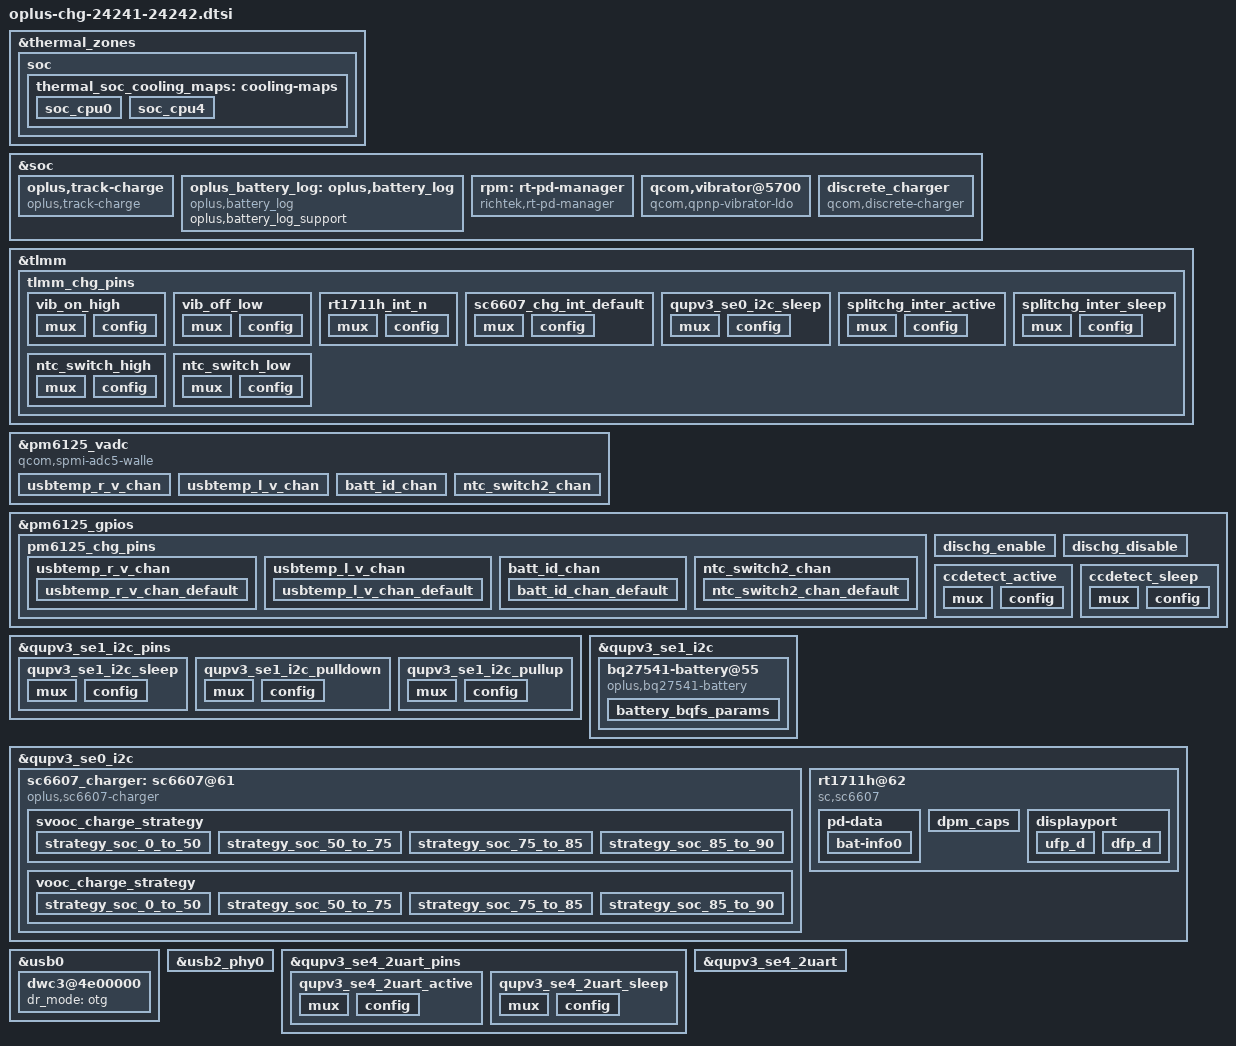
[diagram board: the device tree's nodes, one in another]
#include <dt-bindings/iio/qti_power_supply_iio.h>

&thermal_zones {
	soc {
		thermal_soc_cooling_maps: cooling-maps {
			soc_cpu0 {
				cooling-device =
					<&CPU0 (THERMAL_MAX_LIMIT-4)
						(THERMAL_MAX_LIMIT-4)>;
			};

			soc_cpu4 {
				cooling-device =
					<&CPU4 (THERMAL_MAX_LIMIT-4)
						(THERMAL_MAX_LIMIT-4)>;
			};

			/*soc_cpu6 {
				cooling-device = <&cpu6_isolate 1 1>;
			};

			soc_cpu7 {
				cooling-device = <&cpu7_isolate 1 1>;
			};*/
		};
	};
};

&soc {
	oplus,track-charge {
		compatible = "oplus,track-charge";
		track,fast_chg_break_t_thd = <1000>;
		track,general_chg_break_t_thd = <200>;
		track,voocphy_type = <2>;
		track,wired_max_power = <45000>;
		track,wired_fast_chg_scheme = <4>;
		track,gauge_status_ctrl;
		track,nominal_qmax1 = <5166>;
		track,nominal_fcc1 = <4700>;
		track,external_gauge_num = <1>;
	};

	oplus_battery_log: oplus,battery_log {
		compatible = "oplus,battery_log";
		oplus,battery_log_support;
	};
};

&tlmm {
	tlmm_chg_pins: tlmm_chg_pins {
		vib_on_high: vib_on_high {
			mux {
				pins = "gpio100";
				function = "gpio";
			};

			config {
				pins = "gpio100";
				drive-strength = <2>;
				output-high;
			};
		};
		vib_off_low: vib_off_low {
			mux {
				pins = "gpio100";
				function = "gpio";
			};

			config {
				pins = "gpio100";
				drive-strength = <2>;
				output-low;
			};
		};

		rt1711h_int_n: rt1711h_int_n {
			mux {
				pins = "gpio89";
				function = "gpio";
			};

			config {
				pins = "gpio89";
				drive-strength = <2>;
				bias-disable;
			};
		};

		sc6607_chg_int_default: sc6607_chg_int_default {
			mux {
				pins = "gpio32";
				function = "gpio";
			};

			config {
				pins = "gpio32";
				drive-strength = <2>;
				bias-disable;
			};
		};
		qupv3_se0_i2c_sleep: qupv3_se0_i2c_sleep {
				mux {
					pins = "gpio0", "gpio1";
					function = "gpio";
				};

				config {
					pins = "gpio0", "gpio1";
					drive-strength = <2>;
					bias-no-pull;
					output-high;
				};
		};
		/*split_chg*/
		splitchg_inter_active: splitchg_inter_active {
			mux {
				pins = "gpio32";
				function = "gpio";
			};
			config {
				pins = "gpio32";
				drive-strength = <2>;
				bias-pull-up;
			};
		};

		splitchg_inter_sleep: splitchg_inter_sleep {
			mux {
				pins = "gpio32";
				function = "gpio";
			};
			config {
				pins = "gpio32";
				drive-strength = <2>;
				bias-pull-up;
			};
		};

		ntc_switch_high: ntc_switch_high {
			mux {
				pins = "gpio85";
				function = "gpio";
			};

			config {
				pins = "gpio85";
				drive-strength = <2>;
				output-high;
			};
		};

		ntc_switch_low: ntc_switch_low {
			mux {
				pins = "gpio85";
				function = "gpio";
			};

			config {
				pins = "gpio85";
				drive-strength = <2>;
				output-low;
			};
		};


	};
};

&pm6125_vadc {
	compatible = "qcom,spmi-adc5-walle";
	pinctrl-0 = <&usbtemp_r_v_chan_default &usbtemp_l_v_chan_default &batt_id_chan_default &ntc_switch2_chan_default>;

	usbtemp_r_v_chan {
		reg = <ADC5_GPIO1_100K_PU>;
		label = "usbtemp_r_v_chan";
		qcom,ratiometric;
		qcom,hw-settle-time = <200>;
		qcom,pre-scaling = <1 1>;
		qcom,scale-fn-type = <ADC_SCALE_HW_CALIB_DEFAULT>;
	};

	usbtemp_l_v_chan {
		reg = <ADC5_GPIO2_100K_PU>;
		label = "usbtemp_l_v_chan";
		qcom,ratiometric;
		qcom,hw-settle-time = <200>;
		qcom,pre-scaling = <1 1>;
		qcom,scale-fn-type = <ADC_SCALE_HW_CALIB_DEFAULT>;
	};

	batt_id_chan {
		reg = <ADC5_GPIO3_100K_PU>;
		label = "batt_id_chan";
		qcom,ratiometric;
		qcom,hw-settle-time = <200>;
		qcom,pre-scaling = <1 1>;
		qcom,scale-fn-type = <ADC_SCALE_HW_CALIB_DEFAULT>;
	};

	ntc_switch2_chan {
		reg = <ADC5_GPIO4_100K_PU>;
		label = "ntc_switch2_chan";
		qcom,ratiometric;
		qcom,hw-settle-time = <200>;
		qcom,pre-scaling = <1 1>;
		qcom,scale-fn-type = <ADC_SCALE_HW_CALIB_DEFAULT>;
	};
};

&pm6125_gpios {
	pm6125_chg_pins: pm6125_chg_pins {
			usbtemp_r_v_chan {
				usbtemp_r_v_chan_default: usbtemp_r_v_chan_default {
					pins = "gpio3";
					bias-high-impedance;
				};
			};

			usbtemp_l_v_chan {
				usbtemp_l_v_chan_default: usbtemp_l_v_chan_default {
					pins = "gpio4";
					bias-high-impedance;
				};
			};

			batt_id_chan {
				batt_id_chan_default: batt_id_chan_default {
					pins = "gpio6";
					bias-high-impedance;
				};
			};

			ntc_switch2_chan {
				ntc_switch2_chan_default: ntc_switch2_chan_default {
					pins = "gpio7";
					bias-high-impedance;
				};
			};
	};
	dischg_enable: dischg_enable {
		pins = "gpio8";
		function = "normal";
		power-source = <0>;
		output-high;
		input-disable;
		qcom,drive-strength = <2>;
	};

	dischg_disable: dischg_disable {
		pins = "gpio8";
		function = "normal";
		power-source = <0>;
		output-low;
		input-disable;
		qcom,drive-strength = <2>;
	};

	ccdetect_active: ccdetect_active {
		mux {
			pins = "gpio102";
			function = "gpio";
		};

		config {
			pins = "gpio102";
			drive-strength = <2>;
			input-enable;
			//bias-pull-up; /*PULL UP*/
			bias-disable;
		};
	};

	ccdetect_sleep: ccdetect_sleep {
		mux {
			pins = "gpio102";
			function = "gpio";
		};

		config {
			pins = "gpio102";
			drive-strength = <2>;
			//output-low;
			//bias-pull-down; /*PULL DOWN*/
			input-enable;
			bias-disable;
		};
	};
};

&qupv3_se1_i2c_pins {
	qupv3_se1_i2c_sleep: qupv3_se1_i2c_sleep {
		mux {
			pins = "gpio4", "gpio5";
			function = "gpio";
		};

		config {
			pins = "gpio4", "gpio5";
			drive-strength = <2>;
			bias-no-pull;
			output-high;
		};
	};
	qupv3_se1_i2c_pulldown: qupv3_se1_i2c_pulldown {
		mux {
			pins = "gpio4", "gpio5";
			function = "gpio";
		};

		config {
			pins = "gpio4", "gpio5";
			drive-strength = <2>;
			bias-pull-down;
			output-low;
		};
	};

	qupv3_se1_i2c_pullup: qupv3_se1_i2c_pullup {
		mux {
			pins = "gpio4", "gpio5";
			function = "gpio";
		};

		config {
			pins = "gpio4", "gpio5";
			drive-strength = <2>;
			bias-pull-up;
			input-enable;
		};
	};
};

&qupv3_se1_i2c {
	status = "okay";
	qcom,clk-freq-out = <100000>;
	pinctrl-names = "default", "sleep", "pulldown", "pullup";
	pinctrl-0 = <&qupv3_se1_i2c_active>;
	pinctrl-1 = <&qupv3_se1_i2c_sleep>;
	pinctrl-2 = <&qupv3_se1_i2c_pulldown>;
	pinctrl-3 = <&qupv3_se1_i2c_pullup>;
	bq27541-battery@55 {
		status = "okay";
		compatible = "oplus,bq27541-battery";
		reg = <0x55>;
		io-channels = <&pm6125_vadc ADC5_GPIO3_100K_PU>;
		io-channel-names = "batt_id_chan";
		dep-supply = <&pm6125_vadc>;
		battery_bqfs_params {
			#include "bq27426_bqfs.dtsi"
		};
	};
};


&soc {
	rpm: rt-pd-manager {
		compatible = "richtek,rt-pd-manager";
		#io-channel-cells = <1>;
		io-channels = <&discrete_charger PSY_IIO_PD_ACTIVE>,
			      <&discrete_charger PSY_IIO_PD_USB_SUSPEND_SUPPORTED>,
			      <&discrete_charger PSY_IIO_PD_IN_HARD_RESET>,
			      <&discrete_charger PSY_IIO_PD_CURRENT_MAX>,
			      <&discrete_charger PSY_IIO_PD_VOLTAGE_MIN>,
			      <&discrete_charger PSY_IIO_PD_VOLTAGE_MAX>,
			      <&discrete_charger PSY_IIO_USB_REAL_TYPE>,
			      <&discrete_charger PSY_IIO_PD_SDP>;
		io-channel-names = "pd_active",
				   "pd_usb_suspend_supported",
				   "pd_in_hard_reset",
				   "pd_current_max",
				   "pd_voltage_min",
				   "pd_voltage_max",
				   "real_type",
				   "pd_sdp";
	};
};
/* load vibrator for rm pmic */
&soc {
	qcom,vibrator@5700 {
			compatible = "qcom,qpnp-vibrator-ldo";
			reg = <0x5700 0x100>;
			qcom,vib-ldo-volt-uv = <3000000>;
			qcom,disable-overdrive;
			qcom,vib-type = <1>;	/* 0:ldo 1:gpio */
			status = "okay";

			qcom,vibrator_switch-gpio = <&tlmm 100 0x00>;
			pinctrl-names = "vib_on_high", "vib_off_low";
			pinctrl-0 = <&vib_on_high>;
			pinctrl-1 = <&vib_off_low >;
	};
};

&qupv3_se0_i2c {
	status = "okay";
	pinctrl-0 = <&qupv3_se0_i2c_active>;
	pinctrl-1 = <&qupv3_se0_i2c_sleep>;
	qcom,clk-freq-out = <400000>;
	oplus,i2c-auto-suspend-delay-ms = <3000>;
	sc6607_charger:sc6607@61 {
		status = "okay";
		compatible = "oplus,sc6607-charger";
		reg = <0x61>; /*The device operates as a slave device with address 75H*/

		qcom,chg_irq_gpio = <&tlmm 32 0x00>;
		dpdm-supply = <&usb2_phy0>;
		pinctrl-names = "default",
				"splitchg_inter_active",
				"splitchg_inter_sleep";

		pinctrl-0 = <&sc6607_chg_int_default>;
		pinctrl-1 = <&splitchg_inter_active>;
		pinctrl-2 = <&splitchg_inter_sleep>;

		sc,vsys-limit = <3400>;
		sc,vbat = <4450>;
		sc,charge-curr = <2000>;
		sc,iindpm-disable = <0>;
		sc,input-curr-limit = <500>;
		sc,ico-enable = <0>;
		sc,precharge-volt = <0>;      /* 0:2700mv , 1:3000mv */
		sc,precharge-curr = <500>;
		sc,term-en = <1>;
		sc,term-curr = <100>;     /* ma */
		sc,rechg-dis = <1>;
		sc,boost-voltage = <5000>;
		sc,boost-max-current = <1500>;
		sc,conv-ocp-dis = <0>;
		sc,tsbat-jeita-dis = <1>;
		sc,vpmid-ovp-otg-dis = <0>;
		sc,vbat-ovp-buck-dis = <0>;
		sc,ibat-ocp = <1>;    /* 0:10A , 1:16A */
		ovp_reg = <0x36>; /* 4850mv */
		ocp_reg = <0xf>;    /* 4.75A*/
		sc,charge-detect-enable;
		sc,disable-qc;
		qcom,copycat_vooc_support;
		oplus,copycat_identify_algorithm = <2>;
		oplus,copycat-vooc-count = <4>;

		/*
		 * Charger name
		 * Main charger: primary_chg
		 * Slave charger: secondary_chg
		 */
		charger_name = "primary_chg";

		qcom,voocphy_current_default = <41>;/*4100mA*/

		qcom,svooc_cool_down_current_limit = <100 20 20 24 30 34 40 44 50 54 82 100>;
		qcom,vooc_cool_down_current_limit = <82 20 20 24 30 34 40 44 50 54 82>;
		qcom,abnormal_adapter_current = <82 60 40 40>;
		oplus,workaround_for_100w;
		qcom,vooc_little_cold_full_voltage = <4470>;
		qcom,vooc_cool_full_voltage = <4470>;
		qcom,vooc_warm_full_voltage = <4130>;
		qcom,vooc_1time_full_voltage = <4530>;
		qcom,vooc_ntime_full_voltage = <4520>;
		qcom,low_curr_full_t1 = <120>;
		qcom,low_curr_full_t2 = <350>;
		qcom,low_curr_full_t3 = <430>;
		qcom,range1_low_curr_full = <900 4520
					     800 4515
					     700 4500
					     600 4490
					     500 4480>;
		qcom,range2_low_curr_full = <1000 4520
					     900 4515
					     800 4500
					     700 4490
					     600 4480>;

		qcom,vooc_multistep_initial_batt_temp = <1000>;
		qcom,vooc_little_cool_temp = <200>;
		qcom,vooc_cool_temp = <120>;
		qcom,vooc_little_cold_temp = <50>;
		qcom,vooc_normal_low_temp = <350>;
		qcom,vooc_strategy_normal_current = <82>;
		qcom,vooc_normal_to_little_cool_current = <100>;
		qcom,vooc_batt_over_high_temp = <510>;
		qcom,vooc-low-temp = <0>;
		qcom,vooc-high-temp = <500>;
		qcom,vooc-low-soc = <0>;
		qcom,vooc-high-soc = <90>;
		qcom,vooc-normal-high-temp = <440>;
		qcom,vooc-warm-allow-vol = <4000>;
		qcom,vooc-warm-allow-soc = <50>;
		qcom,impedance_calculation_newmethod;
		qcom,svooc_circuit_r_l = <0x18>;
		qcom,svooc_circuit_r_h = <0x2>;/* 65 mR */

		qcom,vooc_strategy1_batt_high_temp0 = <385>;
		qcom,vooc_strategy1_batt_high_temp1 = <395>;
		qcom,vooc_strategy1_batt_high_temp2 = <420>;
		qcom,vooc_strategy1_batt_low_temp2 = <410>;
		qcom,vooc_strategy1_batt_low_temp1 = <385>;
		qcom,vooc_strategy1_batt_low_temp0 = <375>;

		qcom,vooc_strategy1_high_current0 = <82>;
		qcom,vooc_strategy1_high_current1 = <60>;
		qcom,vooc_strategy1_high_current2 = <40>;
		qcom,vooc_strategy1_low_current2 = <60>;
		qcom,vooc_strategy1_low_current1 = <60>;
		qcom,vooc_strategy1_low_current0 = <82>;

		qcom,vooc_strategy1_high_current0_vooc = <30>;
		qcom,vooc_strategy1_high_current1_vooc = <30>;
		qcom,vooc_strategy1_high_current2_vooc = <30>;
		qcom,vooc_strategy1_low_current2_vooc = <30>;
		qcom,vooc_strategy1_low_current1_vooc = <30>;
		qcom,vooc_strategy1_low_current0_vooc = <30>;

		qcom,voocphy_ibat_over_current = <8500>;
		qcom,voocphy_cp_max_ibus = <4500>;
		qcom,voocphy_svooc_cp_max_ibus = <4500>;
		qcom,voocphy_vooc_cp_max_ibus = <6500>;
		qcom,batt_pwd_curr_thd1 = <4300>;
		qcom,batt_pwd_vol_thd1 = <4514>;

		qcom,voocphy_freq_mincore = <999000>;
		qcom,voocphy_freq_midcore = <1443000>;
		qcom,voocphy_freq_maxcore = <1443000>;
		qcom,voocphy_current_change_timeout = <100>;
		oplus,sc6607_ntc_surport_1000k = <
			(-40) 4251000 (-39) 3962000 (-38) 3695000 (-37) 3447000 (-36) 3218000 (-35) 3005000
			(-34) 2807000 (-33) 2624000 (-32) 2454000 (-31) 2296000 (-30) 2149000 (-29) 2012000
			(-28) 1885000 (-27) 1767000 (-26) 1656000 (-25) 1554000 (-24) 1458000 (-23) 1369000
			(-22) 1286000 (-21) 1208000 (-20) 1135000 (-19) 1068000 (-18) 1004000 (-17) 945000
			(-16) 889600 (-15) 837800 (-14) 789300 (-13) 743900 (-12) 701300 (-11) 661500
			(-10) 624100 (-9) 589000 (-8) 556200 (-7) 525300 (-6) 496300 (-5) 469100
			(-4) 443500 (-3) 419500 (-2) 396900 (-1) 375600 0 355600 1 336800
			2 319100 3 302400 4 286700 5 271800 6 257800 7 244700
			8 232200 9 220500 10 209400 11 198900 12 189000 13 179700
			14 170900 15 162500 16 154600 17 147200 18 140100 19 133400
			20 127000 21 121000 22 115400 23 110000 24 104800 25 100000
			26 95400 27 91040 28 86900 29 82970 30 79230 31 75690
			32 72320 33 69120 34 66070 35 63180 36 60420 37 57810
			38 55310 39 52940 40 50680 41 48530 42 46490 43 44530
			44 42670 45 40900 46 39210 47 37600 48 36060 49 34600
			50 33190 51 31860 52 30580 53 29360 54 28200 55 27090
			56 26030 57 25010 58 24040 59 23110 60 22220 61 21370
			62 20560 63 19780 64 19040 65 18320 66 17640 67 16990
			68 16360 69 15760 70 15180 71 14630 72 14100 73 13600
			74 13110 75 12640 76 12190 77 11760 78 11350 79 10960
			80 10580 81 10210 82 9859 83 9522 84 9198 85 8887
			86 8587 87 8299 88 8022 89 7756 90 7500 91 7254
			92 7016 93 6788 94 6568 95 6357 96 6153 97 5957
			98 5768 99 5586 100 5410 101 5241 102 5078 103 4921
			104 4769 105 4623 106 4482 107 4346 108 4215 109 4088
			110 3966 111 3848 112 3734 113 3624 114 3518 115 3415
			116 3316 117 3220 118 3128 119 3038 120 2952 121 2868
			122 2787 123 2709 124 2634 125 2561 125 2561 125 2561
			125 2561 125 2561 125 2561 125 2561 125 2561 125 2561
			125 2561 125 2561 125 2561 125 2561 125 2561 125 2561>;

		svooc_batt_sys_curve =	<0 1 0 1 0 0 0	// 4000mA
					1 1 1 1 0 0 0	// 4604mV
					0 0 1 1 0 1 0	// 2600mA
					1 1 1 1 0 0 0	// 4604mV
					0 0 0 1 0 1 1	// 1100mA
					1 1 1 1 0 0 0>;	// 4604mV

		vooc_batt_sys_curve =	<0 1 0 1 0 0 0	// 4000mA
					1 1 1 1 0 0 0	// 4604mV
					0 0 1 1 0 1 0	// 2600mA
					1 1 1 1 0 0 0	// 4604mV
					0 0 0 1 0 1 1	// 1100mA
					1 1 1 1 0 0 0>;	// 4604mV

	    svooc_charge_strategy {
			strategy_soc_0_to_50 {
				strategy_temp_little_cold =	<4150 15 0 0 0
								 4460 11 0 0 0
								 4470 10 1 0 0>;
				strategy_temp_cool =		<4150 23 0 0 0
								 4150 20 0 0 0
								 4460 15 0 0 0
								 4470 10 1 0 0>;
				strategy_temp_little_cool = 	<4150 35 0 0 0
								 4150 30 0 0 0
								 4480 28 0 0 0
								 4480 25 0 0 0
								 4480 20 0 0 0
								 4510 18 0 0 0
								 4510 15 0 0 0
								 4520 10 1 0 0>;
				strategy_temp_normal_low = 	<4230 41 0 0 0
								 4230 40 0 0 0
								 4230 35 0 0 0
								 4230 30 0 0 0
								 4480 28 0 0 0
								 4480 25 0 0 0
								 4480 20 0 0 0
								 4510 18 0 0 0
								 4510 15 0 0 0
								 4520 10 1 0 0>;
				strategy_temp_normal_high =	<4230 41 0 0 0
								 4230 40 0 0 0
								 4230 35 0 0 0
								 4230 30 0 0 0
								 4480 28 0 0 0
								 4480 25 0 0 0
								 4480 20 0 0 0
								 4510 18 0 0 0
								 4510 15 0 0 0
								 4520 10 1 0 0>;
				strategy_temp_warm =		<4120 13 0 0 0
								 4130 10 1 0 0>;
			};

			strategy_soc_50_to_75 {
				strategy_temp_little_cold =	<4470 10 1 0 0>;
				strategy_temp_cool =		<4460 15 0 0 0
								 4470 10 1 0 0>;
				strategy_temp_little_cool = 	<4480 20 0 0 0
								 4510 18 0 0 0
								 4510 15 0 0 0
								 4520 10 1 0 0>;
				strategy_temp_normal_low = 	<4480 25 0 0 0
								 4480 20 0 0 0
								 4510 18 0 0 0
								 4510 15 0 0 0
								 4520 10 1 0 0>;
				strategy_temp_normal_high =	<4480 25 0 0 0
								 4480 20 0 0 0
								 4510 18 0 0 0
								 4510 15 0 0 0
								 4520 10 1 0 0>;
				strategy_temp_warm =		<4130 10 1 0 0>;//no fastcharge
			};

			strategy_soc_75_to_85 {
				strategy_temp_little_cold = 	<4470 10 1 0 0>;
				strategy_temp_cool =		<4470 10 1 0 0>;
				strategy_temp_little_cool =	<4510 15 0 0 0
								 4520 10 1 0 0>;
				strategy_temp_normal_low =	<4510 15 0 0 0
								 4520 10 1 0 0>;
				strategy_temp_normal_high =	<4510 15 0 0 0
								 4520 10 1 0 0>;
				strategy_temp_warm =		<4130 10 1 0 0>;//no fastcharge
			};

			strategy_soc_85_to_90 {
				strategy_temp_little_cold = 	<4470 10 1 0 0>;
				strategy_temp_cool =		<4470 10 1 0 0>;
				strategy_temp_little_cool =	<4520 10 1 0 0>;
				strategy_temp_normal_low =	<4520 10 1 0 0>;
				strategy_temp_normal_high =	<4520 10 1 0 0>;
				strategy_temp_warm =		<4130 10 1 0 0>;//no fastcharge
			};
		};

		vooc_charge_strategy {
			strategy_soc_0_to_50 {
				strategy_temp_little_cold =	<4150 30 0 0 0
								 4460 22 0 0 0
								 4470 20 1 0 0>;
				strategy_temp_cool =		<4460 30 0 0 0
								 4470 20 1 0 0>;
				strategy_temp_little_cool =	<4510 30 0 0 0
								 4520 20 1 0 0>;
				strategy_temp_normal_low =	<4510 30 0 0 0
								 4520 20 1 0 0>;
				strategy_temp_normal_high =	<4510 30 0 0 0
								 4520 20 1 0 0>;
				strategy_temp_warm =		<4120 26 0 0 0
								 4130 20 1 0 0>;
			};

			strategy_soc_50_to_75 {
				strategy_temp_little_cold =	<4470 20 1 0 0>;
				strategy_temp_cool =		<4460 30 0 0 0
								 4470 20 1 0 0>;
				strategy_temp_little_cool =	<4510 30 0 0 0
								 4520 20 1 0 0>;
				strategy_temp_normal_low =	<4510 30 0 0 0
								 4520 20 1 0 0>;
				strategy_temp_normal_high =	<4510 30 0 0 0
								 4520 20 1 0 0>;
				strategy_temp_warm =		<4130 20 1 0 0>;
			};

			strategy_soc_75_to_85 {
				strategy_temp_little_cold =	<4470 20 1 0 0>;
				strategy_temp_cool =		<4470 20 1 0 0>;
				strategy_temp_little_cool =	<4510 30 0 0 0
								 4520 20 1 0 0>;
				strategy_temp_normal_low =	<4510 30 0 0 0
								 4520 20 1 0 0>;
				strategy_temp_normal_high =	<4510 30 0 0 0
								 4520 20 1 0 0>;
				strategy_temp_warm =		<4130 20 1 0 0>;
			};

			strategy_soc_85_to_90 {
				strategy_temp_little_cold =	<4470 20 1 0 0>;
				strategy_temp_cool =		<4470 20 1 0 0>;
				strategy_temp_little_cool =	<4520 20 1 0 0>;
				strategy_temp_normal_low =	<4520 20 1 0 0>;
				strategy_temp_normal_high =	<4520 20 1 0 0>;
				strategy_temp_warm =		<4130 20 1 0 0>;
			};
		};
	};


	rt1711h@62 {
		compatible = "sc,sc6607";
		reg = <0x62>;
		status = "okay";
		tcpc-dual,supported_modes = <0>; /* 0: dfp/ufp, */
						 /* 1: dfp, 2: ufp */
		rt-tcpc,name = "type_c_port0"; /* tcpc_device's name */
		rt-tcpc,role_def = <1>; /* 0: Unknown, 1: SNK, 2: SRC */
					/* 3: DRP, 4: Try.SRC, 5: Try.SNK */
		rt-tcpc,rp_level = <0>; /* 0: Default, 1: 1.5, 2: 3.0 */
		rt-tcpc,vconn_supply  = <1>;  /* 0: Never, 1: Always, */
					      /* 2: EMarkOnly, 3: StartOnly */
		rt-tcpc,notifier_supply_num = <2>;
		/* rt-tcpc,disable_pe; */
		rt1711pd,intr_gpio = <&tlmm 89 0x0>;
		rt1711pd,intr_gpio_num = <89>;
		rt,disable_irq_reset;
		pinctrl-names = "default";
		pinctrl-0 = <&rt1711h_int_n>;
		pd-data {
			pd,vid = <0x311c>;
			pd,pid = <0x6600>;
			pd,source-cap-ext = /bits/ 8 <0x1c 0x31 0x00 0x66
						      0x00 0x00 0x00 0x00
						      0x00 0x00 0x00 0x00
						      0x00 0x00 0x00 0x00
						      0x00 0x00 0x00 0x00
						      0x00 0x00 0x01 0x05
						      0x00>;
			pd,sink-cap-ext = /bits/ 8 <0x1c 0x31 0x00 0x66
							   0x00 0x00 0x00 0x00
							   0x01 0x00 0x00 0x00
							   0x00 0x00 0x00 0x00
							   0x01 0x00 0x00 0x00
							   0x00 0x00 0x00 0x00>;
			pd,mfrs = "RichtekTCPC";

			/*
			 *	VSAFE5V = 0, MAX_POWER = 1, CUSTOM = 2,
			 *	MAX_POWER_LV = 0x21, MAX_POWER_LVIC = 0x31
			 *	MAX_POWER_HV = 0x41, MAX_POWER_HVIC = 0x51
			 */
			pd,charging_policy= <0>;

			/*
			 * Fixed 5V, 500 mA <0x00019032>
			 * Fixed 5V, 1A <0x00019064>
			 * Fixed 5V, 2A <0x000190c8>
			 * Fixed 5V, 3A <0x0001912c>
			 * Fixed 9V, 500 mA <0x0002d032>
			 * Fixed 9V, 1A <0x0002d064>
			 * Fixed 9V, 2A <0x0002d0c8>
			 * Fixed 9V, 3A <0x0002d12c>
			 * Variable 5-9V, 1A <0x8642d064>
			 * Variable 5-9V, 2A <0x8642d0c8>
			 * Variable 5-9V, 3A <0x8642d12c>
			 */
			pd,source-pdo-size = <1>;
			pd,source-pdo-data = <0x00019064>;
			pd,sink-pdo-size = <3>;
			pd,sink-pdo-data = <0x360190c8 0x0002d096 0xc0dc3252>;

			/*
			 * No DP, host + device
			 *	pd,id-vdo-size = <6>;
			 *	pd,id-vdo-data = <0xd14029cf 0x0 0x17110000
						  0x41800000 0x0 0x21800000>;
			 * With DP
			 *	pd,id-vdo-size = <6>;
			 *	pd,id-vdo-data = <0xd54029cf 0x0 0x17110000
						  0x41800000 0x0 0x21800000>;
			 */

			pd,id-vdo-size = <6>;
			pd,id-vdo-data = <0xd14029cf 0x0 0x17110000
					  0x41800000 0x0 0x21800000>;

			bat,nr = <1>;
			pd,country_nr = <0>;

			bat-info0 {
				bat,vid = <0x311c>;
				bat,pid = <0x6600>;
				bat,mfrs = "bat1";
				bat,design_cap = <17>;
			};

			//bat-info1 {
			//	bat,vid = <0x8abc>;
			//	bat,pid = <0x5234>;
			//	bat,mfrs = "bat2";
			//	bat,design_cap = <4000>;
			//};

			//country0 {
			//	pd,country_code = <0x5457>;
			//	pd,country_len = <2>; /* max len = 26 */
			//	pd,country_data = <0xff 0xff>;
			//};

			//country1 {
			//	pd,country_code = <0x5553>;
			//	pd,country_len = <3>; /* max len = 26 */
			//	pd,country_data = <0xf1 0xf2 0xf3>;
			//};
		};
		dpm_caps {
			local_dr_power;
			local_dr_data;
			//local_ext_power;
			local_usb_comm;
			//local_usb_suspend;
			//local_high_cap;
			//local_give_back;
			local_no_suspend;
			local_vconn_supply;

			//attempt_discover_cable_dfp;
			//attempt_enter_dp_mode;
			attempt_discover_cable;
			attempt_discover_id;
			attempt_discover_svid;

			/* 0: disable, 1: prefer_snk, 2: prefer_src */
			pr_check = <0>;
			//pr_reject_as_source;
			//pr_reject_as_sink;
			//pr_check_gp_source;
			//pr_check_gp_sink;

			/* 0: disable, 1: prefer_ufp, 2: prefer_dfp */
			dr_check = <0>;
			//dr_reject_as_dfp;
			//dr_reject_as_ufp;
		};
		displayport {
			/* connection type = "both", "ufp_d", "dfp_d" */
			1st_connection = "dfp_d";
			2nd_connection = "dfp_d";
			signal,dp_v13;
			//signal,dp_gen2;
			//usbr20_not_used;
			typec,receptacle;
			ufp_d {
				//pin_assignment,mode_a;
				//pin_assignment,mode_b;
				//pin_assignment,mode_c;
				//pin_assignment,mode_d;
				//pin_assignment,mode_e;
			};
			dfp_d {
				//pin_assignment,mode_a;
				//pin_assignment,mode_b;
				pin_assignment,mode_c;
				pin_assignment,mode_d;
				pin_assignment,mode_e;
				//pin_assignment,mode_f;
			};
		};
	};
};

&soc {
	discrete_charger: discrete_charger {
		compatible = "qcom,discrete-charger";
		status = "okay";

		oplus,chg_ops = "ext-sc6607";
		#io-channel-cells = <1>;
		io-channels = <&pm6125_vadc ADC5_GPIO1_100K_PU>,
				      <&pm6125_vadc ADC5_GPIO2_100K_PU>,
					  <&pm6125_vadc ADC5_GPIO3_100K_PU>,
					  <&pm6125_vadc ADC5_GPIO4_100K_PU>;
		io-channel-names = "usbtemp_r_v_chan",
				"usbtemp_l_v_chan",
				"batt_id_chan",
				"ntc_switch2_chan";
		dep-supply = <&pm6125_vadc>;
        //ntc switch gpio
        qcom,ntc-switch-gpio = <&tlmm 85 0x00>;

		pinctrl-names = "dischg_enable", "dischg_disable","ccdetect_active", "ccdetect_sleep",
				       "ntc_switch_high", "ntc_switch_low";

		pinctrl-0 = <&dischg_enable>;
		pinctrl-1 = <&dischg_disable>;
		pinctrl-2 = <&ccdetect_active>;
		pinctrl-3 = <&ccdetect_sleep>;
		pinctrl-4 = <&ntc_switch_high>;
		pinctrl-5 = <&ntc_switch_low>;

		qcom,support_abnormal_adapter;
		qcom,input_current_charger_ma = <2000>;
		qcom,pd_input_current_charger_ma = <1500>;
		qcom,qc_input_current_charger_ma = <2000>;
		qcom,input_current_usb_ma = <500>;
		qcom,input_current_cdp_ma = <1500>;
		qcom,input_current_camera_ma = <1200>;
		qcom,input_current_calling_ma = <1500>;

		qcom,led_warm_bat_decidegc = <350>;
		qcom,led_high_bat_decidegc = <370>;
		qcom,input_current_led_ma = <1200>;
		qcom,input_current_led_ma_high = <1200>;
		qcom,input_current_led_ma_warm = <1500>;
		qcom,input_current_led_ma_normal = <2000>;

		qcom,vooc_temp_bat_normal_decidegc = <350>;
		qcom,vooc_temp_bat_warm_decidegc = <370>;
		qcom,vooc_temp_bat_hot_decidegc = <440>;
		qcom,input_current_vooc_led_ma_high = <1200>;
		qcom,input_current_vooc_led_ma_warm = <1800>;
		qcom,input_current_vooc_led_ma_normal = <3600>;
		qcom,input_current_vooc_ma_normal = <3600>;

		qcom,input_current_vooc_ma_warm = <3200>;

		qcom,input_current_vooc_ma_high = <2200>;

		qcom,charger_current_vooc_ma_normal = <1800>;

		qcom,iterm_disabled = <0>;
		qcom,iterm_ma = <250>;
		qcom,recharge-mv = <100>;
		qcom,batt_capacity_mah = <5000>;/*typical capacity*/

		qcom,removed_bat_decidegc = <390>;  /*<-39C*/

		qcom,cold_bat_decidegc = <100>;  /*-10C~0C*/
		qcom,temp_cold_vfloat_mv = <4470>;
		qcom,temp_cold_fastchg_current_ma = <731>;
		qcom,temp_cold_fastchg_current_ma_high = <731>;
		qcom,temp_cold_fastchg_current_ma_low = <731>;
		qcom,pd_temp_cold_fastchg_current_ma_high = <731>;
		qcom,pd_temp_cold_fastchg_current_ma_low = <731>;
		qcom,qc_temp_cold_fastchg_current_ma_high = <731>;
		qcom,qc_temp_cold_fastchg_current_ma_low = <731>;

		qcom,little_cold_bat_decidegc = <0>;    /*0C~5C*/
		qcom,temp_little_cold_vfloat_mv = <4470>;
		qcom,temp_little_cold_fastchg_current_ma_high = <2200>;
		qcom,temp_little_cold_fastchg_current_ma_low = <2200>;
		qcom,temp_little_cold_fastchg_current_ma = <2200>;
		qcom,pd_temp_little_cold_fastchg_current_ma_high = <2200>;
		qcom,pd_temp_little_cold_fastchg_current_ma_low = <3200>;
		qcom,qc_temp_little_cold_fastchg_current_ma_high = <2200>;
		qcom,qc_temp_little_cold_fastchg_current_ma_low = <3200>;

		qcom,cool_bat_decidegc = <50>;  /*5C~12C*/
		qcom,temp_cool_vfloat_mv = <4470>;
		qcom,temp_cool_fastchg_current_ma_high = <2200>;
		qcom,temp_cool_fastchg_current_ma_low = <2200>;
		qcom,pd_temp_cool_fastchg_current_ma_high = <3100>;
		qcom,pd_temp_cool_fastchg_current_ma_low = <3300>;

		qcom,little_cool_bat_decidegc = <120>;  /*12C~16C*/
		qcom,temp_little_cool_vfloat_mv = <4470>;
		qcom,temp_little_cool_fastchg_current_ma = <2200>;
		qcom,pd_temp_little_cool_fastchg_current_ma = <3000>;

		qcom,normal_bat_decidegc = <160>;       /*16C~45C*/
		qcom,temp_normal_vfloat_mv = <4470>;
		qcom,temp_normal_fastchg_current_ma = <2200>;
		qcom,pd_temp_normal_fastchg_current_ma = <3300>;

		qcom,warm_bat_decidegc = <450>;         /*45C~53C*/ /*8pin Bat Vooc project need add 3 degree C*/
		qcom,temp_warm_vfloat_mv = <4130>;
		qcom,temp_warm_fastchg_current_ma = <2200>;
		qcom,pd_temp_warm_fastchg_current_ma = <2700>;
		qcom,temp_warm_fastchg_current_ma_led_on = <1000>;

		qcom,hot_bat_decidegc = <530>;

		qcom,non_standard_vfloat_mv = <3980>;
		qcom,non_standard_fastchg_current_ma = <500>;

		qcom,short_c_bat_cv_mv = <4330>;
		qcom,short_c_bat_vfloat_mv = <3800>;
		qcom,short_c_bat_fastchg_current_ma = <512>;

		qcom,cold_vfloat_sw_limit = <4420>;
		qcom,little_cold_vfloat_sw_limit = <4420>;
		qcom,cool_vfloat_sw_limit = <4420>;
		qcom,little_cool_vfloat_sw_limit = <4420>;
		qcom,normal_vfloat_sw_limit = <4420>;
		qcom,warm_vfloat_sw_limit = <4080>;
		qcom,non_standard_vfloat_sw_limit = <3930>;
		qcom,short_c_bat_vfloat_sw_limit = <3750>;

		qcom,max_chg_time_sec = <64800>;
		qcom,charger_hv_thr = <10000>;
		qcom,charger_recv_thr = <9800>;
		qcom,charger_lv_thr = <3400>;
		qcom,vbatt_full_thr = <4435>;
		qcom,vbatt_hv_thr = <4600>;

		qcom,vfloat_step_mv = <8>;
		qcom,cold_vfloat_over_sw_limit = <4480>;
		qcom,little_cold_vfloat_over_sw_limit = <4480>;
		qcom,cool_vfloat_over_sw_limit = <4480>;
		qcom,little_cool_vfloat_over_sw_limit = <4480>;
		qcom,normal_vfloat_over_sw_limit = <4480>;
		qcom,warm_vfloat_over_sw_limit = <4140>;
		qcom,non_standard_vfloat_over_sw_limit = <3990>;

		qcom,vbatt_power_off = <3300>;
		qcom,vbatt_soc_1 = <3410>;
		qcom,vooc_project = <21>;
		qcom,vbatt_num = <1>;
		qcom,voocphy_support = <2>;
		//qcom,chargerid_support;
		qcom,external_gauge;
		qcom,ffc_support;
		qcom,dual_ffc;
		qcom,sc6607_switch_ntc;
		oplus,aging_ffc_version = <1>;
		qcom,smart_charging_screenoff;
		qcom,vooc_show_ui_soc_decimal;
		qcom,ui_soc_decimal_speedmin = <20>;//2A
		qcom,otg_scheme = <1>;//0:cid 1:ccdetect_gpio 2:switch
		qcom,ccdetect-gpio = <&tlmm 102 0x00>;
		oplus,boot_reset_adapter;
		qcom,check_batt_full_by_sw;
		qcom,chg_ctrl_by_lcd;
		qcom,chg_ctrl_by_camera;
		qcom,chg_ctrl_by_calling;
		qcom,support_ntc_01c_precision;
		qcom,sw_vfloat_over_protect_enable;

		qcom,normal_vterm_hw_inc = <18>;
		qcom,non_normal_vterm_hw_inc = <18>;
		qcom,usbtemp_batttemp_gap = <12>;

		qcom,ff1_normal_fastchg_ma = <1500>;
		qcom,ff1_warm_fastchg_ma = <1500>;

		qcom,ffc2_normal_fastchg_ma = <900>;/*12C~35c*/
		qcom,ffc2_warm_fastchg_ma = <950>;/*35C~40c*/
		qcom,ffc2_temp_low_decidegc = <120>;
		qcom,ffc2_temp_warm_decidegc = <350>;
		qcom,ffc2_temp_high_decidegc = <400>;

		qcom,ff1_exit_step_ma = <1300>;
		qcom,ff1_warm_exit_step_ma = <1300>;
		qcom,ffc2_exit_step_ma = <800>;
		qcom,ffc2_warm_exit_step_ma = <850>;

		qcom,ffc_normal_vfloat_sw_limit = <4515>;
		qcom,ffc_temp_normal_vfloat_mv = <4600>;
		qcom,ffc_normal_vfloat_over_sw_limit = <4600>;
		qcom,ffc_warm_vfloat_sw_limit = <4515>;

		qcom,ffc2_normal_vfloat_sw_limit = <4515>;
		qcom,ffc2_temp_normal_vfloat_mv = <4600>;
		qcom,ffc2_normal_vfloat_over_sw_limit = <4600>;
		qcom,ffc2_warm_vfloat_sw_limit = <4515>;
		full-pre-ffc-mv = <4465>;
		full_pre_ffc_judge;

		qcom,default_iterm_ma = <254>;
		qcom,default_temp_normal_fastchg_current_ma = <2200>;
		qcom,default_normal_vfloat_sw_limit = <4420>;
		qcom,default_temp_normal_vfloat_mv = <4470>;
		qcom,default_normal_vfloat_over_sw_limit = <4480>;

		qcom,default_temp_little_cool_fastchg_current_ma = <2200>;
		qcom,default_little_cool_vfloat_sw_limit = <4420>;
		qcom,default_temp_little_cool_vfloat_mv = <4470>;
		qcom,default_little_cool_vfloat_over_sw_limit = <4480>;

		//for PD9V or QC9V
		qcom,vbatt_pdqc_to_5v_thr = <4500>;
		qcom,vbatt_pdqc_to_9v_thr = <4500>;

		//GPIO config:
		//qcom,chargerid_switch-gpio = <&tlmm 50 0x00>;
		qcom,dischg-gpio = <&pm6125_gpios 8 0x00>;
		qcom,usbtemp_chan_tmp;

		qcom,vooc-max-input-volt-support = <11000>;     //11V
		qcom,vooc-max-input-current-support = <4100>;   //4.1A
		qcom,use_vooc_charging_animation;
		qcom,qc_not_support = <1>;
		qcom,support_3p6_standard;
		qcom,usb_ntc_pullup = <100000>;
		qcom,mastercharger_psy_set;
		oplus,use_external_cclogic;
		qcom,support_usbtemp_protect_v2;
		qcom,usbtemp_batt_temp_low = <50>;
		qcom,usbtemp_batt_temp_high = <50>;
		qcom,usbtemp_ntc_temp_low = <57>;
		qcom,usbtemp_ntc_temp_high = <69>;
		qcom,usbtemp_temp_gap_low_with_batt_temp = <7>;
		qcom,usbtemp_temp_gap_high_with_batt_temp = <12>;
		qcom,usbtemp_temp_gap_low_without_batt_temp = <12>;
		qcom,usbtemp_temp_gap_high_without_batt_temp = <24>;
		qcom,usbtemp_rise_fast_temp_low = <3>;
		qcom,usbtemp_rise_fast_temp_high = <3>;
		qcom,usbtemp_rise_fast_temp_count_low = <30>;
		qcom,usbtemp_rise_fast_temp_count_high = <20>;

		qcom,usbtemp_cool_down_ntc_low = <54>;
		qcom,usbtemp_cool_down_ntc_high = <65>;
		qcom,usbtemp_cool_down_gap_low = <12>;
		qcom,usbtemp_cool_down_gap_high = <20>;
		qcom,usbtemp_cool_down_recover_ntc_low = <48>;
		qcom,usbtemp_cool_down_recover_ntc_high = <60>;
		qcom,usbtemp_cool_down_recover_gap_low = <6>;
		qcom,usbtemp_cool_down_recover_gap_high = <15>;

		qcom,gsm_call_on;
		qcom,smart_chg_soh_support;
		oplus,smooth_switch_v2;
		oplus,reserve_chg_soc = <2>;
		oplus,reserve_dis_soc = <2>;

		qcom,usb_btb_support;
		//qcom,batt_btb_support;
		qcom,pa_thermal_support;
		//qcom,batt_thermal_support;
		qcom,bb_thermal_support;
		qcom,charger_thermal_support;
		qcom,quiet_thermal_support;
		qcom,flash_thermal_support;
		oplus,support_hot_enter_kpoc;
		oplus,poweroff_high_batt_temp = <720>;
		oplus,poweroff_emergency_batt_temp = <770>;
		oplus,usbtemp_batt_temp_over_hot = <60>;
		oplus,usbtemp_temp_gap_with_batt_temp_in_over_hot = <15>;

		oplus,uart_tx-gpio = <&tlmm 12 0x00>;
		oplus,uart_rx-gpio = <&tlmm 13 0x00>;
	};
};

&usb0 {
	dpdm-supply = <&usb2_phy0>;
	extcon = <&rpm>;
	#io-channel-cells = <1>;
	io-channels= <&discrete_charger PSY_IIO_USB_REAL_TYPE>;
	io-channel-names = "chg_type";
	dwc3@4e00000 {
		dr_mode = "otg";
	};
};

&usb2_phy0 {
	qcom,param-override-seq =
		<0x67 0x6c	/* override_x0 */
		 0xCF 0x70	/* override_x1 */
		 0x2e 0x74	/* override x2 */
		 0x03 0x78>;	/* override x3 */
	qcom,param-override-seq-host =
		<0x67 0x6c	/* override_x0 */
		 0xCD 0x70	/* override_x1 */
		 0x2e 0x74	/* override x2 */
		 0x03 0x78>;	/* override x3 */
};

&qupv3_se4_2uart_pins{
	qupv3_se4_2uart_active: qupv3_se4_2uart_active {
		mux {
			pins = "gpio12", "gpio13";
			function = "qup4";
		};

		config {
			pins = "gpio12", "gpio13";
			drive-strength = <2>;
			bias-disable;
		};
	};

	qupv3_se4_2uart_sleep: qupv3_se4_2uart_sleep {
		mux {
			pins = "gpio12", "gpio13";
			function = "gpio";
		};

		config {
			pins = "gpio12", "gpio13";
			drive-strength = <2>;
			bias-pull-down;
			input-enable;
		};
	};
};

&qupv3_se4_2uart {
	pinctrl-names = "default", "sleep";
	pinctrl-0 = <&qupv3_se4_2uart_active>;
	pinctrl-1 = <&qupv3_se4_2uart_sleep>;
	status = "ok";
};
